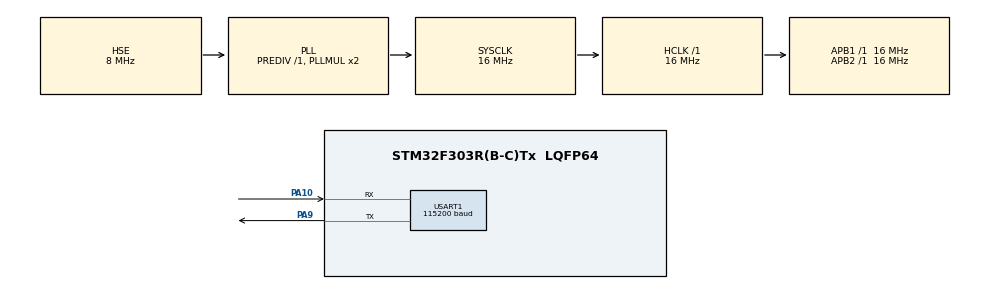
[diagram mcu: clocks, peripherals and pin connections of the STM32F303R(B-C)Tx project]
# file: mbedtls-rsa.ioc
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Mcu.Family=STM32F3
Mcu.Name=STM32F303R(B-C)Tx
Mcu.Package=LQFP64
NVIC.PriorityGroup=NVIC_PRIORITYGROUP_4
PA10.Mode=Asynchronous
PA10.Signal=USART1_RX
PA9.Mode=Asynchronous
PA9.Signal=USART1_TX
PF0-OSC_IN.Mode=HSE-External-Oscillator
PF0-OSC_IN.Signal=RCC_OSC_IN
PF1-OSC_OUT.Mode=HSE-External-Oscillator
PF1-OSC_OUT.Signal=RCC_OSC_OUT
ProjectManager.HeapSize=0x200
ProjectManager.StackSize=0x1000
ProjectManager.TargetToolchain=STM32CubeIDE
RCC.AHBFreq_Value=16000000
RCC.APB1Freq_Value=16000000
RCC.APB1TimFreq_Value=16000000
RCC.APB2Freq_Value=16000000
RCC.APB2TimFreq_Value=16000000
RCC.CortexFreq_Value=16000000
RCC.HCLKFreq_Value=16000000
RCC.HSE_VALUE=8000000
RCC.HSI_VALUE=8000000
RCC.LSE_VALUE=32768
RCC.PLLSourceVirtual=RCC_PLLSOURCE_HSE
RCC.SYSCLKFreq_VALUE=16000000
RCC.SYSCLKSourceVirtual=RCC_SYSCLKSOURCE_PLLCLK
RCC.USBFreq_Value=16000000
USART1.BaudRate=115200
USART1.VirtualMode-Asynchronous=VM_ASYNC
board=custom

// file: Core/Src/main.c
/* USER CODE BEGIN Header */
/**
  ******************************************************************************
  * @file           : main.c
  * @brief          : Main program body
  ******************************************************************************
  * @attention
  *
  * Copyright (c) 2024 STMicroelectronics.
  * All rights reserved.
  *
  * This software is licensed under terms that can be found in the LICENSE file
  * in the root directory of this software component.
  * If no LICENSE file comes with this software, it is provided AS-IS.
  *
  ******************************************************************************
  */
/* USER CODE END Header */
#include "main.h"

/* USER CODE BEGIN Includes */
#include "mbedtls/pk.h"
#include "mbedtls/md.h"
#include "mbedtls/entropy.h"
#include "mbedtls/base64.h"
#include "mbedtls/ctr_drbg.h"
#include "string.h"
#define MLEN 16
#define HASH_LEN 32    //sha256
#define KEY_SIZE 512  //bit
#define SIG_SIZE 64  //byte
/* USER CODE END Includes */

UART_HandleTypeDef huart1;

void SystemClock_Config(void);
static void MX_GPIO_Init(void);
static void MX_USART1_UART_Init(void);

int main(void)
{

  /* USER CODE BEGIN 1 */
	 int ret = 0;
	 int vry = 0;
	 uint8_t msg[MLEN];
	 uint8_t sig[KEY_SIZE];
	 uint8_t hash[32];
	 const char *pers = "simple_rsa_sign";
	 uint8_t ok[4] = {0x74, 0x72, 0x75, 0x65};

	 mbedtls_rsa_context ctx;
	 mbedtls_entropy_context entropy;
	 mbedtls_ctr_drbg_context ctr_drbg;

	 mbedtls_md_context_t sha256_ctx;

	 mbedtls_entropy_init(&entropy);
	 mbedtls_ctr_drbg_init(&ctr_drbg);

	 //initialize the RSA key pair; padding mode PSS, hash algorithm SHA256
	 mbedtls_rsa_init(&ctx, MBEDTLS_RSA_PKCS_V21, MBEDTLS_MD_SHA256);
	 mbedtls_ctr_drbg_seed(&ctr_drbg, mbedtls_entropy_func, &entropy, (const unsigned char *) pers, strlen(pers));

	 //generate the RSA key pair
	 mbedtls_rsa_gen_key(&ctx, mbedtls_ctr_drbg_random, &ctr_drbg, KEY_SIZE, 65537);	//public exponent

  /* USER CODE END 1 */

  /* MCU Configuration--------------------------------------------------------*/

  /* Reset of all peripherals, Initializes the Flash interface and the Systick. */
  HAL_Init();

  /* Configure the system clock */
  SystemClock_Config();

  /* Initialize all configured peripherals */
  MX_GPIO_Init();
  MX_USART1_UART_Init();

  /* Infinite loop */
  /* USER CODE BEGIN WHILE */
  while (1)
  {
	  ret = HAL_UART_Receive(&huart1, msg, MLEN, HAL_MAX_DELAY);
	  if(ret==HAL_OK)
	  {
		 mbedtls_md_init(&sha256_ctx);
		 mbedtls_md_setup(&sha256_ctx, mbedtls_md_info_from_type(MBEDTLS_MD_SHA256), 0);
		 mbedtls_md_starts(&sha256_ctx);
		 mbedtls_md_update(&sha256_ctx, msg, MLEN);
		 mbedtls_md_finish(&sha256_ctx, hash);
		 mbedtls_md_free(&sha256_ctx);
		  __disable_irq();  // disable interrupts
	  	  HAL_GPIO_WritePin(GPIOA, GPIO_PIN_6, 1); // drive the level high before the operation as a trigger signal
	  	  //sign with the RSA private key; output the signature result sig
	  	  mbedtls_rsa_pkcs1_sign(&ctx, mbedtls_ctr_drbg_random, &ctr_drbg, MBEDTLS_RSA_PRIVATE, MBEDTLS_MD_SHA256, HASH_LEN, hash, sig);
	  	  HAL_GPIO_WritePin(GPIOA, GPIO_PIN_6, 0); // drive the level low after the operation
	  	  __enable_irq();  // enable interrupts
	  	  HAL_UART_Transmit(&huart1, sig, SIG_SIZE, HAL_MAX_DELAY);

	  	  __disable_irq();  // disable interrupts
	  	  HAL_GPIO_WritePin(GPIOA, GPIO_PIN_6, 1); // drive the level high before the operation as a trigger signal
	  	  //verify with the RSA public key; returns 0 on success
	  	  vry = mbedtls_rsa_pkcs1_verify(&ctx, mbedtls_ctr_drbg_random, &ctr_drbg, MBEDTLS_RSA_PUBLIC, MBEDTLS_MD_SHA256, HASH_LEN, hash, sig);
	   	  HAL_GPIO_WritePin(GPIOA, GPIO_PIN_6, 0); // drive the level low after the operation
	   	  __enable_irq();  // enable interrupts
	  	  if(vry == 0){
	  		HAL_UART_Transmit(&huart1, ok, 4, HAL_MAX_DELAY);
	  	  }
	  }

    /* USER CODE END WHILE */

    /* USER CODE BEGIN 3 */
  }
//  // clean up resources
//  mbedtls_rsa_free(&ctx);
//  mbedtls_ctr_drbg_free(&ctr_drbg);
//  mbedtls_entropy_free(&entropy);
  /* USER CODE END 3 */
}

void SystemClock_Config(void)
{
  RCC_OscInitTypeDef RCC_OscInitStruct = {0};
  RCC_ClkInitTypeDef RCC_ClkInitStruct = {0};
  RCC_PeriphCLKInitTypeDef PeriphClkInit = {0};

  /** Initializes the RCC Oscillators according to the specified parameters
  * in the RCC_OscInitTypeDef structure.
  */
  RCC_OscInitStruct.OscillatorType = RCC_OSCILLATORTYPE_HSE;
  RCC_OscInitStruct.HSEState = RCC_HSE_ON;
  RCC_OscInitStruct.HSEPredivValue = RCC_HSE_PREDIV_DIV1;
  RCC_OscInitStruct.HSIState = RCC_HSI_ON;
  RCC_OscInitStruct.PLL.PLLState = RCC_PLL_ON;
  RCC_OscInitStruct.PLL.PLLSource = RCC_PLLSOURCE_HSE;
  RCC_OscInitStruct.PLL.PLLMUL = RCC_PLL_MUL2;
  if (HAL_RCC_OscConfig(&RCC_OscInitStruct) != HAL_OK)
  {
    Error_Handler();
  }

  /** Initializes the CPU, AHB and APB buses clocks
  */
  RCC_ClkInitStruct.ClockType = RCC_CLOCKTYPE_HCLK|RCC_CLOCKTYPE_SYSCLK
                              |RCC_CLOCKTYPE_PCLK1|RCC_CLOCKTYPE_PCLK2;
  RCC_ClkInitStruct.SYSCLKSource = RCC_SYSCLKSOURCE_PLLCLK;
  RCC_ClkInitStruct.AHBCLKDivider = RCC_SYSCLK_DIV1;
  RCC_ClkInitStruct.APB1CLKDivider = RCC_HCLK_DIV1;
  RCC_ClkInitStruct.APB2CLKDivider = RCC_HCLK_DIV1;

  if (HAL_RCC_ClockConfig(&RCC_ClkInitStruct, FLASH_LATENCY_0) != HAL_OK)
  {
    Error_Handler();
  }
  PeriphClkInit.PeriphClockSelection = RCC_PERIPHCLK_USART1;
  PeriphClkInit.Usart1ClockSelection = RCC_USART1CLKSOURCE_PCLK2;
  if (HAL_RCCEx_PeriphCLKConfig(&PeriphClkInit) != HAL_OK)
  {
    Error_Handler();
  }
}

static void MX_USART1_UART_Init(void)
{

  huart1.Instance = USART1;
  huart1.Init.BaudRate = 115200;
  huart1.Init.WordLength = UART_WORDLENGTH_8B;
  huart1.Init.StopBits = UART_STOPBITS_1;
  huart1.Init.Parity = UART_PARITY_NONE;
  huart1.Init.Mode = UART_MODE_TX_RX;
  huart1.Init.HwFlowCtl = UART_HWCONTROL_NONE;
  huart1.Init.OverSampling = UART_OVERSAMPLING_16;
  huart1.Init.OneBitSampling = UART_ONE_BIT_SAMPLE_DISABLE;
  huart1.AdvancedInit.AdvFeatureInit = UART_ADVFEATURE_NO_INIT;
  if (HAL_UART_Init(&huart1) != HAL_OK)
  {
    Error_Handler();
  }

}

static void MX_GPIO_Init(void)
{

  /* GPIO Ports Clock Enable */
  __HAL_RCC_GPIOF_CLK_ENABLE();
  __HAL_RCC_GPIOA_CLK_ENABLE();

}

void Error_Handler(void)
{
  __disable_irq();
  while (1)
  {
  }
}
